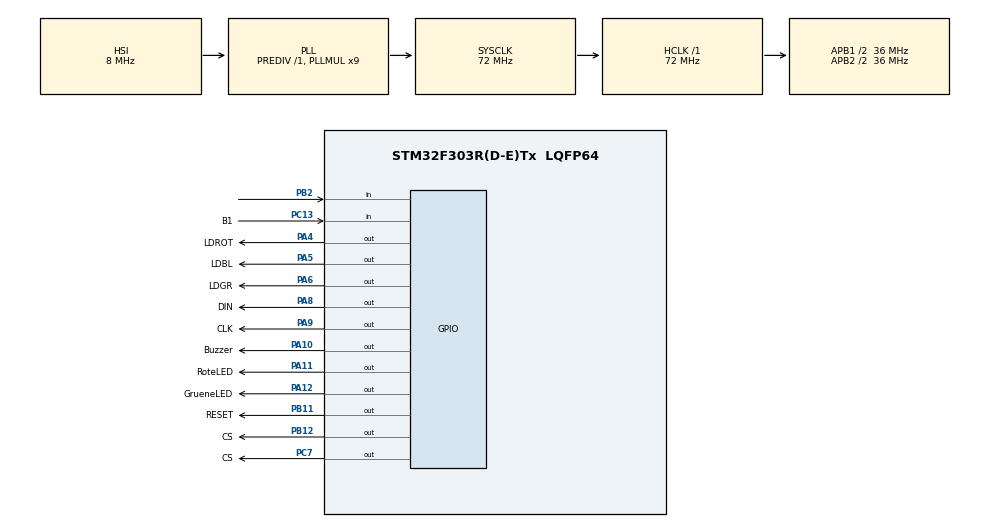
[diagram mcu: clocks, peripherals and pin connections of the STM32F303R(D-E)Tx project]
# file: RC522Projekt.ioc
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ADC1.Channel-2\#ChannelRegularConversion=ADC_CHANNEL_2
ADC1.NbrOfConversionFlag=1
ADC1.Offset-2\#ChannelRegularConversion=0
ADC1.OffsetNumber-2\#ChannelRegularConversion=ADC_OFFSET_NONE
ADC1.Rank-2\#ChannelRegularConversion=1
ADC1.SamplingTime-2\#ChannelRegularConversion=ADC_SAMPLETIME_1CYCLE_5
ADC1.master=1
I2C1.Timing=0x00201D2B
Mcu.Family=STM32F3
Mcu.Name=STM32F303R(D-E)Tx
Mcu.Package=LQFP64
NVIC.ForceEnableDMAInit=true
NVIC.PriorityFilter=0
NVIC.TIM6_DAC1_IRQn=true\:0\:0\:false\:false\:true\:true\:true\:true
PA0.GPIO_PuPd=GPIO_PULLDOWN
PA0.Signal=S_TIM2_CH1
PA1.Signal=ADC1_IN2
PA10.GPIO_Label=Buzzer
PA10.Signal=GPIO_Output
PA11.GPIO_Label=RoteLED
PA11.Signal=GPIO_Output
PA12.GPIO_Label=GrueneLED
PA12.Signal=GPIO_Output
PA15.GPIO_PuPd=GPIO_PULLUP
PA15.Signal=I2C1_SCL
PA4.GPIO_Label=LDROT
PA4.Signal=GPIO_Output
PA5.GPIO_Label=LDBL
PA5.Signal=GPIO_Output
PA6.GPIO_Label=LDGR
PA6.Signal=GPIO_Output
PA8.GPIO_Label=DIN
PA8.Signal=GPIO_Output
PA9.GPIO_Label=CLK
PA9.Signal=GPIO_Output
PB11.GPIO_Label=RESET
PB11.Signal=GPIO_Output
PB12.GPIO_Label=CS
PB12.Signal=GPIO_Output
PB13.Signal=SPI2_SCK
PB14.Signal=SPI2_MISO
PB15.Signal=SPI2_MOSI
PB2.GPIO_PuPd=GPIO_PULLUP
PB2.Signal=GPIO_Input
PB7.GPIO_PuPd=GPIO_PULLUP
PB7.Signal=I2C1_SDA
PC13.GPIO_Label=B1
PC13.Signal=GPIO_Input
PC7.GPIO_Label=CS
PC7.Signal=GPIO_Output
ProjectManager.HeapSize=0x200
ProjectManager.StackSize=0x400
ProjectManager.TargetToolchain=STM32CubeIDE
RCC.AHBFreq_Value=72000000
RCC.APB1CLKDivider=RCC_HCLK_DIV2
RCC.APB1Freq_Value=36000000
RCC.APB1TimFreq_Value=72000000
RCC.APB2CLKDivider=RCC_HCLK_DIV2
RCC.APB2Freq_Value=36000000
RCC.APB2TimFreq_Value=72000000
RCC.CortexFreq_Value=72000000
RCC.HCLKFreq_Value=72000000
RCC.HSE_VALUE=8000000
RCC.HSI_VALUE=8000000
RCC.PLLMUL=RCC_PLL_MUL9
RCC.SYSCLKFreq_VALUE=72000000
RCC.SYSCLKSource=RCC_SYSCLKSOURCE_PLLCLK
RCC.USBFreq_Value=48000000
SPI2.BaudRatePrescaler=SPI_BAUDRATEPRESCALER_32
SPI2.CLKPhase=SPI_PHASE_1EDGE
SPI2.CLKPolarity=SPI_POLARITY_LOW
SPI2.CalculateBaudRate=1.125 MBits/s
SPI2.DataSize=SPI_DATASIZE_8BIT
SPI2.Direction=SPI_DIRECTION_2LINES
SPI2.Mode=SPI_MODE_MASTER
SPI2.NSS=SPI_NSS_SOFT
TIM2.Channel-PWM\ Generation1\ CH1=TIM_CHANNEL_1
TIM2.Period=1000-1
TIM2.Prescaler=1440-1
TIM6.Period=36000-1
TIM6.Prescaler=2-1
VP_TIM2_VS_ControllerModePWMFunctional.Mode=PWM Generation1 CH1
VP_TIM6_VS_ClockSourceINT.Mode=Enable_Timer
board=custom

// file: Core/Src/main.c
/* USER CODE BEGIN Header */
/**
  ******************************************************************************
  * @file           : main.c
  * @brief          : Main program body
  ******************************************************************************
  * @attention
  *
  * Copyright (c) 2026 STMicroelectronics.
  * All rights reserved.
  *
  * This software is licensed under terms that can be found in the LICENSE file
  * in the root directory of this software component.
  * If no LICENSE file comes with this software, it is provided AS-IS.
  *
  ******************************************************************************
  */
/* USER CODE END Header */
#include "main.h"

/* USER CODE BEGIN Includes */
#include <stdio.h>
#include "MFRC522_STM32.h"
#include "ssd1306.h"
#include "ssd1306_fonts.h"
#include "ssd1306_conf.h"
#include "access_control.h"
#include <stdbool.h>
#include "servo.h"
#include "joystick.h"
/* USER CODE END Includes */

ADC_HandleTypeDef hadc1;

I2C_HandleTypeDef hi2c1;

SPI_HandleTypeDef hspi2;

TIM_HandleTypeDef htim2;
TIM_HandleTypeDef htim6;

/* USER CODE BEGIN PV */
volatile float aktuelle_position = 90.0f;
volatile int8_t speed_faktor = 1;
volatile bool sweep_modus = false;
/* USER CODE END PV */

void SystemClock_Config(void);
static void MX_GPIO_Init(void);
static void MX_SPI2_Init(void);
static void MX_I2C1_Init(void);
static void MX_TIM2_Init(void);
static void MX_TIM6_Init(void);
static void MX_ADC1_Init(void);
/* USER CODE BEGIN PFP */
static void Display_Aktualisieren(void);
/* USER CODE END PFP */

/* USER CODE BEGIN 0 */
MFRC522_t rfID = {&hspi2, CS_GPIO_Port, CS_Pin, RESET_GPIO_Port, RESET_Pin};

// Aktualisierung der OLED-Anzeige (SSD1306, 128x64) ueber I2C
static void Display_Aktualisieren(void)
{
    static uint32_t letztes_update = 0;
    static int8_t vorheriges_entsperrt = -1;
    static int8_t vorheriger_alarm = -1;
    static bool vorheriger_admin_lockout = false;
    static uint8_t vorherige_fehlversuche_in_folge = 0;
    static int8_t vorheriger_speed = -1;
    static int vorheriger_winkel = -1;
    static LearnState_t vorheriger_learn_state = LEARN_INAKTIV;
    static uint32_t vorherige_restzeit = 0;
    static bool vorheriger_sweep = false;
    static bool vorheriger_falsch_gesperrt = false;

    // Rate-Limiting fuer I2C-Uebertragungen zur Vermeidung von Bus-Blockaden
    uint32_t min_intervall = sweep_modus ? 150 : 50;
    if (HAL_GetTick() - letztes_update < min_intervall) {
        return;
    }

    bool entsperrt = AccessControl_IsUnlocked();
    bool alarm = AccessControl_AlarmAktiv();
    bool admin_lockout = AccessControl_IsAdminLockout();
    uint8_t fehlversuche_in_folge = AccessControl_GetConsecutiveFailures();
    int winkel_int = (int)aktuelle_position;
    LearnState_t learn_state = AccessControl_GetLearnState();
    uint32_t restzeit = AccessControl_GetLearnTimeoutRemaining();
    bool falsch_gesperrt = AccessControl_IsWrongCardBlocked();

    // Redraw nur bei Zustandsaenderungen durchfuehren
    if (entsperrt == vorheriges_entsperrt &&
        alarm == vorheriger_alarm &&
        admin_lockout == vorheriger_admin_lockout &&
        fehlversuche_in_folge == vorherige_fehlversuche_in_folge &&
        speed_faktor == vorheriger_speed &&
        winkel_int == vorheriger_winkel &&
        learn_state == vorheriger_learn_state &&
        restzeit == vorherige_restzeit &&
        sweep_modus == vorheriger_sweep &&
        falsch_gesperrt == vorheriger_falsch_gesperrt) {
        return;
    }

    letztes_update = HAL_GetTick();
    vorheriges_entsperrt = entsperrt;
    vorheriger_alarm = alarm;
    vorheriger_admin_lockout = admin_lockout;
    vorherige_fehlversuche_in_folge = fehlversuche_in_folge;
    vorheriger_speed = speed_faktor;
    vorheriger_winkel = winkel_int;
    vorheriger_learn_state = learn_state;
    vorherige_restzeit = restzeit;
    vorheriger_sweep = sweep_modus;
    vorheriger_falsch_gesperrt = falsch_gesperrt;

    ssd1306_Fill(Black);

    char buffer[32];

    if (admin_lockout) {
        // Anzeige: Sicherheits-Lockout nach 5 Fehlversuchen
        ssd1306_SetCursor(15, 6);
        ssd1306_WriteString("GESPERRT!", Font_11x18, White);
        ssd1306_SetCursor(15, 26);
        ssd1306_WriteString("5 Fehlversuche", Font_7x10, White);
        ssd1306_SetCursor(1, 39);
        ssd1306_WriteString("Admin-Karte noetig", Font_7x10, White);
        ssd1306_SetCursor(15, 51);
        ssd1306_WriteString("zum Entsperren", Font_7x10, White);
    } else if (learn_state != LEARN_INAKTIV) {
        // Anzeige: Zweistufiger Anlernmodus
        if (learn_state == LEARN_WARTE_NEUE_KARTE) {
            ssd1306_SetCursor(5, 4);
            ssd1306_WriteString("1. NEUE KARTE", Font_7x10, White);
            ssd1306_SetCursor(5, 20);
            ssd1306_WriteString("Karte anhalten", Font_7x10, White);
            sprintf(buffer, "Timeout: %lu s", restzeit);
            ssd1306_SetCursor(5, 36);
            ssd1306_WriteString(buffer, Font_7x10, White);
            ssd1306_SetCursor(5, 52);
            ssd1306_WriteString("B1: Abbruch", Font_7x10, White);
        } else if (learn_state == LEARN_WARTE_ADMIN_KARTE) {
            ssd1306_SetCursor(5, 4);
            ssd1306_WriteString("2. BESTAETIGEN", Font_7x10, White);
            ssd1306_SetCursor(5, 20);
            ssd1306_WriteString("Admin vorhalten", Font_7x10, White);
            sprintf(buffer, "Timeout: %lu s", restzeit);
            ssd1306_SetCursor(5, 36);
            ssd1306_WriteString(buffer, Font_7x10, White);
            ssd1306_SetCursor(5, 52);
            ssd1306_WriteString("B1: Abbruch", Font_7x10, White);
        } else if (learn_state == LEARN_ERFOLGREICH) {
            ssd1306_SetCursor(25, 12);
            ssd1306_WriteString("ERFOLG!", Font_11x18, White);
            ssd1306_SetCursor(5, 36);
            ssd1306_WriteString("Karte gespeichert", Font_7x10, White);
        } else if (learn_state == LEARN_BEREITS_BEKANNT) {
            ssd1306_SetCursor(25, 12);
            ssd1306_WriteString("HINWEIS", Font_11x18, White);
            ssd1306_SetCursor(8, 36);
            ssd1306_WriteString("Bereits bekannt!", Font_7x10, White);
        } else {
            ssd1306_SetCursor(25, 12);
            ssd1306_WriteString("ABBRUCH", Font_11x18, White);
            ssd1306_SetCursor(8, 36);
            ssd1306_WriteString("Nicht bestaetigt", Font_7x10, White);
        }
    } else if (alarm) {
        // Anzeige: Alarmzustand mit Fehlversuchs-Zaehler
        ssd1306_SetCursor(30, 6);
        ssd1306_WriteString("ALARM!", Font_11x18, White);
        if (fehlversuche_in_folge > 0) {
            snprintf(buffer, sizeof(buffer), "Fehlversuch %u/5", fehlversuche_in_folge);
            ssd1306_SetCursor(11, 27);
            ssd1306_WriteString(buffer, Font_7x10, White);
        } else {
            ssd1306_SetCursor(18, 27);
            ssd1306_WriteString("Kein Zutritt!", Font_7x10, White);
        }
        ssd1306_SetCursor(18, 40);
        ssd1306_WriteString("Kein Zutritt!", Font_7x10, White);
        ssd1306_SetCursor(15, 52);
        ssd1306_WriteString("B1: Quittieren", Font_7x10, White);
    } else if (entsperrt) {
        if (falsch_gesperrt) {
            // Warnanzeige: Verriegelung durch abweichende UID abgewiesen
            ssd1306_SetCursor(20, 4);
            ssd1306_WriteString("ACHTUNG!", Font_11x18, White);
            ssd1306_SetCursor(15, 25);
            ssd1306_WriteString("Falsche Karte!", Font_7x10, White);
            ssd1306_SetCursor(8, 38);
            ssd1306_WriteString("Nur Freischalter", Font_7x10, White);
            ssd1306_SetCursor(18, 50);
            ssd1306_WriteString("kann sperren!", Font_7x10, White);
        } else {
            // Anzeige: System freigegeben
            snprintf(buffer, sizeof(buffer), "Hallo %s!", AccessControl_GetActiveCardName());
            ssd1306_SetCursor(5, 4);
            ssd1306_WriteString(buffer, Font_7x10, White);

            if (sweep_modus) {
                sprintf(buffer, "SWEEP >>> Spd:%d", speed_faktor);
            } else {
                sprintf(buffer, "W:%3d*   Spd:%d", winkel_int, speed_faktor);
            }
            ssd1306_SetCursor(5, 18);
            ssd1306_WriteString(buffer, Font_7x10, White);

            // Grafische Balkenanzeige fuer den Servowinkel
            ssd1306_DrawRectangle(5, 34, 122, 46, White);
            uint8_t bar_width = (uint8_t)(((uint32_t)winkel_int * 114) / 180);
            if (bar_width > 0) {
                if (bar_width > 114) bar_width = 114;
                ssd1306_FillRectangle(7, 36, 7 + bar_width, 44, White);
            }

            ssd1306_SetCursor(5, 50);
            ssd1306_WriteString("0*           180*", Font_7x10, White);
        }
    } else {
        // Anzeige: System verriegelt
        ssd1306_SetCursor(20, 6);
        ssd1306_WriteString("GESPERRT", Font_11x18, White);
        ssd1306_SetCursor(15, 28);
        ssd1306_WriteString("Karte oder PIN", Font_7x10, White);
        sprintf(buffer, "OK:%lu  Fehl:%lu", AccessControl_GetSuccessfulScans(), AccessControl_GetFailedScans());
        ssd1306_SetCursor(5, 40);
        ssd1306_WriteString(buffer, Font_7x10, White);
        ssd1306_SetCursor(18, 52);
        ssd1306_WriteString("B1: Anlernen", Font_7x10, White);
    }

    ssd1306_UpdateScreen();
}
/* USER CODE END 0 */

int main(void)
{

  /* MCU Configuration--------------------------------------------------------*/

  /* Reset of all peripherals, Initializes the Flash interface and the Systick. */
  HAL_Init();

  /* Configure the system clock */
  SystemClock_Config();

  /* Initialize all configured peripherals */
  MX_GPIO_Init();
  MX_SPI2_Init();
  MX_I2C1_Init();
  MX_TIM2_Init();
  MX_TIM6_Init();
  MX_ADC1_Init();
  /* USER CODE BEGIN 2 */
  ssd1306_Init();
  ssd1306_Fill(Black);
  ssd1306_SetCursor(10, 20);
  ssd1306_WriteString("Starte...", Font_11x18, White);
  ssd1306_UpdateScreen();

  // Peripheriemodule und Treiber initialisieren
  MFRC522_Init(&rfID);
  AccessControl_Init(&rfID);
  Servo_Init(&htim2, TIM_CHANNEL_1);
  Servo_SetAngle(90);
  Joystick_Init(&hadc1, ADC_CHANNEL_2, ADC_CHANNEL_3, SW_GPIO_Port, SW_Pin);

  // Basis-Timer TIM6 fuer zyklische Regler- und Steuerungs-Tasks starten
  HAL_TIM_Base_Start_IT(&htim6);

  /* USER CODE END 2 */

  /* Infinite loop */
  /* USER CODE BEGIN WHILE */
  uint32_t letzte_aktivitaet = HAL_GetTick();
  bool b1_war_gedrueckt = false;
  bool system_war_entsperrt = false;

  while (1)
  {
      // 1. RFID-Task abarbeiten (Polling, Transponder-Erkennung, Timeout-Management)
      AccessControl_Task();

      // Flankenerkennung der Freigabe: Aktivitaetszeitstempel synchronisieren
      bool system_ist_entsperrt = AccessControl_IsUnlocked();
      if (system_ist_entsperrt && !system_war_entsperrt) {
          letzte_aktivitaet = HAL_GetTick();
      }
      system_war_entsperrt = system_ist_entsperrt;

      // 2. Taster B1 (PC13) abfragen (Entprellung per Flankenerkennung)
      bool b1_ist_gedrueckt = (HAL_GPIO_ReadPin(B1_GPIO_Port, B1_Pin) == GPIO_PIN_RESET);
      if (b1_ist_gedrueckt && !b1_war_gedrueckt) {
          if (AccessControl_IsAdminLockout()) {
              // Im Sicherheits-Lockout sind Tasteraktionen gesperrt
          } else if (AccessControl_AlarmAktiv()) {
              AccessControl_ResetAlarm(); // Alarm quittieren
          } else if (AccessControl_GetState() == STATUS_ANLERNEN) {
              AccessControl_CancelLearn(); // Anlernmodus manuell abbrechen
          } else {
              AccessControl_StartLearn();  // Zweistufigen Anlernprozess initialisieren
          }
      }
      b1_war_gedrueckt = b1_ist_gedrueckt;

      // 3. Joystick-Abtastung im 10-ms-Raster
      static uint32_t lastJoyCheck = 0;
      if (HAL_GetTick() - lastJoyCheck >= 10) {
          lastJoyCheck = HAL_GetTick();
          Joystick_Update();

          // Im verriegelten Zustand: Auswertung der PIN-Gestenabfolge (gesperrt bei Admin-Lockout)
          if (!AccessControl_IsUnlocked() && !AccessControl_IsAdminLockout()) {
              if (Joystick_CheckSecretPin()) {
                  AccessControl_UnlockViaPin();
                  letzte_aktivitaet = HAL_GetTick();
              }
          }
      }

      // 4. Betriebsmodi bei aktivem Systemzugriff
      if (AccessControl_IsUnlocked()) {
          // Kurzer Tasterklick: Geschwindigkeitsstufe zyklisch inkrementieren (1..4)
          if (Joystick_GetButtonClicked()) {
              if (++speed_faktor > 4) {
                  speed_faktor = 1;
              }
              letzte_aktivitaet = HAL_GetTick();
          }

          // Langer Tastendruck (> 800 ms): Automatischen Sweep-Modus umschalten
          if (Joystick_GetButtonHeld()) {
              sweep_modus = !sweep_modus;
              letzte_aktivitaet = HAL_GetTick();
          }

          // Manuelle Achsenabweichung: Aktivitaets-Timer zuruecksetzen, bei starker Auslenkung Sweep beenden
          int32_t x_abw = Joystick_GetX();
          if (x_abw < -100 || x_abw > 100) {
              letzte_aktivitaet = HAL_GetTick();
              if (sweep_modus && (x_abw < -400 || x_abw > 400)) {
                  sweep_modus = false;
              }
          }

          // Bei aktivem Sweep: Auto-Lock durch fortlaufende Bewegung zurueckstellen
          if (sweep_modus) {
              letzte_aktivitaet = HAL_GetTick();
          }

          // Auto-Lock: Nach 15 Sekunden ohne Interaktion automatisch verriegeln
          if (!sweep_modus && (HAL_GetTick() - letzte_aktivitaet >= 15000)) {
              AccessControl_Lock();
              sweep_modus = false;
              Servo_SetAngle(90);
              aktuelle_position = 90.0f;
              letzte_aktivitaet = HAL_GetTick();
          }
      } else {
          // Im verriegelten Zustand Sweep deaktivieren
          sweep_modus = false;
      }

      // 5. Displayausgabe aktualisieren
      Display_Aktualisieren();

    /* USER CODE END WHILE */

  }
}

void SystemClock_Config(void)
{
  RCC_OscInitTypeDef RCC_OscInitStruct = {0};
  RCC_ClkInitTypeDef RCC_ClkInitStruct = {0};
  RCC_PeriphCLKInitTypeDef PeriphClkInit = {0};

  /** Initializes the RCC Oscillators according to the specified parameters
  * in the RCC_OscInitTypeDef structure.
  */
  RCC_OscInitStruct.OscillatorType = RCC_OSCILLATORTYPE_HSI;
  RCC_OscInitStruct.HSIState = RCC_HSI_ON;
  RCC_OscInitStruct.HSICalibrationValue = RCC_HSICALIBRATION_DEFAULT;
  RCC_OscInitStruct.PLL.PLLState = RCC_PLL_ON;
  RCC_OscInitStruct.PLL.PLLSource = RCC_PLLSOURCE_HSI;
  RCC_OscInitStruct.PLL.PLLMUL = RCC_PLL_MUL9;
  RCC_OscInitStruct.PLL.PREDIV = RCC_PREDIV_DIV1;
  if (HAL_RCC_OscConfig(&RCC_OscInitStruct) != HAL_OK)
  {
    Error_Handler();
  }

  /** Initializes the CPU, AHB and APB buses clocks
  */
  RCC_ClkInitStruct.ClockType = RCC_CLOCKTYPE_HCLK|RCC_CLOCKTYPE_SYSCLK
                              |RCC_CLOCKTYPE_PCLK1|RCC_CLOCKTYPE_PCLK2;
  RCC_ClkInitStruct.SYSCLKSource = RCC_SYSCLKSOURCE_PLLCLK;
  RCC_ClkInitStruct.AHBCLKDivider = RCC_SYSCLK_DIV1;
  RCC_ClkInitStruct.APB1CLKDivider = RCC_HCLK_DIV2;
  RCC_ClkInitStruct.APB2CLKDivider = RCC_HCLK_DIV2;

  if (HAL_RCC_ClockConfig(&RCC_ClkInitStruct, FLASH_LATENCY_2) != HAL_OK)
  {
    Error_Handler();
  }
  PeriphClkInit.PeriphClockSelection = RCC_PERIPHCLK_I2C1|RCC_PERIPHCLK_ADC12
                              |RCC_PERIPHCLK_TIM2;
  PeriphClkInit.Adc12ClockSelection = RCC_ADC12PLLCLK_DIV1;
  PeriphClkInit.I2c1ClockSelection = RCC_I2C1CLKSOURCE_HSI;
  PeriphClkInit.Tim2ClockSelection = RCC_TIM2CLK_HCLK;
  if (HAL_RCCEx_PeriphCLKConfig(&PeriphClkInit) != HAL_OK)
  {
    Error_Handler();
  }
}

static void MX_ADC1_Init(void)
{

  ADC_MultiModeTypeDef multimode = {0};
  ADC_ChannelConfTypeDef sConfig = {0};

  /** Common config
  */
  hadc1.Instance = ADC1;
  hadc1.Init.ClockPrescaler = ADC_CLOCK_ASYNC_DIV1;
  hadc1.Init.Resolution = ADC_RESOLUTION_12B;
  hadc1.Init.ScanConvMode = ADC_SCAN_DISABLE;
  hadc1.Init.ContinuousConvMode = DISABLE;
  hadc1.Init.DiscontinuousConvMode = DISABLE;
  hadc1.Init.ExternalTrigConvEdge = ADC_EXTERNALTRIGCONVEDGE_NONE;
  hadc1.Init.ExternalTrigConv = ADC_SOFTWARE_START;
  hadc1.Init.DataAlign = ADC_DATAALIGN_RIGHT;
  hadc1.Init.NbrOfConversion = 1;
  hadc1.Init.DMAContinuousRequests = DISABLE;
  hadc1.Init.EOCSelection = ADC_EOC_SINGLE_CONV;
  hadc1.Init.LowPowerAutoWait = DISABLE;
  hadc1.Init.Overrun = ADC_OVR_DATA_OVERWRITTEN;
  if (HAL_ADC_Init(&hadc1) != HAL_OK)
  {
    Error_Handler();
  }

  /** Configure the ADC multi-mode
  */
  multimode.Mode = ADC_MODE_INDEPENDENT;
  if (HAL_ADCEx_MultiModeConfigChannel(&hadc1, &multimode) != HAL_OK)
  {
    Error_Handler();
  }

  /** Configure Regular Channel
  */
  sConfig.Channel = ADC_CHANNEL_2;
  sConfig.Rank = ADC_REGULAR_RANK_1;
  sConfig.SingleDiff = ADC_SINGLE_ENDED;
  sConfig.SamplingTime = ADC_SAMPLETIME_1CYCLE_5;
  sConfig.OffsetNumber = ADC_OFFSET_NONE;
  sConfig.Offset = 0;
  if (HAL_ADC_ConfigChannel(&hadc1, &sConfig) != HAL_OK)
  {
    Error_Handler();
  }

}

static void MX_I2C1_Init(void)
{

  hi2c1.Instance = I2C1;
  hi2c1.Init.Timing = 0x00201D2B;
  hi2c1.Init.OwnAddress1 = 0;
  hi2c1.Init.AddressingMode = I2C_ADDRESSINGMODE_7BIT;
  hi2c1.Init.DualAddressMode = I2C_DUALADDRESS_DISABLE;
  hi2c1.Init.OwnAddress2 = 0;
  hi2c1.Init.OwnAddress2Masks = I2C_OA2_NOMASK;
  hi2c1.Init.GeneralCallMode = I2C_GENERALCALL_DISABLE;
  hi2c1.Init.NoStretchMode = I2C_NOSTRETCH_DISABLE;
  if (HAL_I2C_Init(&hi2c1) != HAL_OK)
  {
    Error_Handler();
  }

  /** Configure Analogue filter
  */
  if (HAL_I2CEx_ConfigAnalogFilter(&hi2c1, I2C_ANALOGFILTER_ENABLE) != HAL_OK)
  {
    Error_Handler();
  }

  /** Configure Digital filter
  */
  if (HAL_I2CEx_ConfigDigitalFilter(&hi2c1, 0) != HAL_OK)
  {
    Error_Handler();
  }

}

static void MX_SPI2_Init(void)
{

  /* SPI2 parameter configuration*/
  hspi2.Instance = SPI2;
  hspi2.Init.Mode = SPI_MODE_MASTER;
  hspi2.Init.Direction = SPI_DIRECTION_2LINES;
  hspi2.Init.DataSize = SPI_DATASIZE_8BIT;
  hspi2.Init.CLKPolarity = SPI_POLARITY_LOW;
  hspi2.Init.CLKPhase = SPI_PHASE_1EDGE;
  hspi2.Init.NSS = SPI_NSS_SOFT;
  hspi2.Init.BaudRatePrescaler = SPI_BAUDRATEPRESCALER_32;
  hspi2.Init.FirstBit = SPI_FIRSTBIT_MSB;
  hspi2.Init.TIMode = SPI_TIMODE_DISABLE;
  hspi2.Init.CRCCalculation = SPI_CRCCALCULATION_DISABLE;
  hspi2.Init.CRCPolynomial = 7;
  hspi2.Init.CRCLength = SPI_CRC_LENGTH_DATASIZE;
  hspi2.Init.NSSPMode = SPI_NSS_PULSE_ENABLE;
  if (HAL_SPI_Init(&hspi2) != HAL_OK)
  {
    Error_Handler();
  }

}

static void MX_TIM2_Init(void)
{

  TIM_ClockConfigTypeDef sClockSourceConfig = {0};
  TIM_MasterConfigTypeDef sMasterConfig = {0};
  TIM_OC_InitTypeDef sConfigOC = {0};

  htim2.Instance = TIM2;
  htim2.Init.Prescaler = 1440-1;
  htim2.Init.CounterMode = TIM_COUNTERMODE_UP;
  htim2.Init.Period = 1000-1;
  htim2.Init.ClockDivision = TIM_CLOCKDIVISION_DIV1;
  htim2.Init.AutoReloadPreload = TIM_AUTORELOAD_PRELOAD_DISABLE;
  if (HAL_TIM_Base_Init(&htim2) != HAL_OK)
  {
    Error_Handler();
  }
  sClockSourceConfig.ClockSource = TIM_CLOCKSOURCE_INTERNAL;
  if (HAL_TIM_ConfigClockSource(&htim2, &sClockSourceConfig) != HAL_OK)
  {
    Error_Handler();
  }
  if (HAL_TIM_PWM_Init(&htim2) != HAL_OK)
  {
    Error_Handler();
  }
  sMasterConfig.MasterOutputTrigger = TIM_TRGO_RESET;
  sMasterConfig.MasterSlaveMode = TIM_MASTERSLAVEMODE_DISABLE;
  if (HAL_TIMEx_MasterConfigSynchronization(&htim2, &sMasterConfig) != HAL_OK)
  {
    Error_Handler();
  }
  sConfigOC.OCMode = TIM_OCMODE_PWM1;
  sConfigOC.Pulse = 0;
  sConfigOC.OCPolarity = TIM_OCPOLARITY_HIGH;
  sConfigOC.OCFastMode = TIM_OCFAST_DISABLE;
  if (HAL_TIM_PWM_ConfigChannel(&htim2, &sConfigOC, TIM_CHANNEL_1) != HAL_OK)
  {
    Error_Handler();
  }
  HAL_TIM_MspPostInit(&htim2);

}

static void MX_TIM6_Init(void)
{

  TIM_MasterConfigTypeDef sMasterConfig = {0};

  htim6.Instance = TIM6;
  htim6.Init.Prescaler = 2-1;
  htim6.Init.CounterMode = TIM_COUNTERMODE_UP;
  htim6.Init.Period = 36000-1;
  htim6.Init.AutoReloadPreload = TIM_AUTORELOAD_PRELOAD_DISABLE;
  if (HAL_TIM_Base_Init(&htim6) != HAL_OK)
  {
    Error_Handler();
  }
  sMasterConfig.MasterOutputTrigger = TIM_TRGO_RESET;
  sMasterConfig.MasterSlaveMode = TIM_MASTERSLAVEMODE_DISABLE;
  if (HAL_TIMEx_MasterConfigSynchronization(&htim6, &sMasterConfig) != HAL_OK)
  {
    Error_Handler();
  }

}

static void MX_GPIO_Init(void)
{
  GPIO_InitTypeDef GPIO_InitStruct = {0};

  /* GPIO Ports Clock Enable */
  __HAL_RCC_GPIOC_CLK_ENABLE();
  __HAL_RCC_GPIOF_CLK_ENABLE();
  __HAL_RCC_GPIOA_CLK_ENABLE();
  __HAL_RCC_GPIOB_CLK_ENABLE();

  /*Configure GPIO pin Output Level */
  HAL_GPIO_WritePin(GPIOA, LDROT_Pin|LDBL_Pin|LDGR_Pin, GPIO_PIN_RESET);

  /*Configure GPIO pin Output Level */
  HAL_GPIO_WritePin(GPIOB, RESET_Pin|CS_Pin, GPIO_PIN_RESET);

  /*Configure GPIO pin : B1_Pin */
  GPIO_InitStruct.Pin = B1_Pin;
  GPIO_InitStruct.Mode = GPIO_MODE_IT_FALLING;
  GPIO_InitStruct.Pull = GPIO_NOPULL;
  HAL_GPIO_Init(B1_GPIO_Port, &GPIO_InitStruct);

  /*Configure GPIO pin : SW_Pin */
  GPIO_InitStruct.Pin = SW_Pin;
  GPIO_InitStruct.Mode = GPIO_MODE_INPUT;
  GPIO_InitStruct.Pull = GPIO_PULLUP;
  HAL_GPIO_Init(SW_GPIO_Port, &GPIO_InitStruct);

  /*Configure GPIO pins : LDROT_Pin LDBL_Pin LDGR_Pin */
  GPIO_InitStruct.Pin = LDROT_Pin|LDBL_Pin|LDGR_Pin;
  GPIO_InitStruct.Mode = GPIO_MODE_OUTPUT_PP;
  GPIO_InitStruct.Pull = GPIO_NOPULL;
  GPIO_InitStruct.Speed = GPIO_SPEED_FREQ_LOW;
  HAL_GPIO_Init(GPIOA, &GPIO_InitStruct);

  /*Configure GPIO pins : RESET_Pin CS_Pin */
  GPIO_InitStruct.Pin = RESET_Pin|CS_Pin;
  GPIO_InitStruct.Mode = GPIO_MODE_OUTPUT_PP;
  GPIO_InitStruct.Pull = GPIO_NOPULL;
  GPIO_InitStruct.Speed = GPIO_SPEED_FREQ_LOW;
  HAL_GPIO_Init(GPIOB, &GPIO_InitStruct);

}

/* USER CODE BEGIN 4 */

void HAL_TIM_PeriodElapsedCallback(TIM_HandleTypeDef *htim) {
    if (htim->Instance == TIM6) {
        static uint8_t joyTick = 0;
        if (++joyTick >= 10) {
            joyTick = 0;

            // Im verriegelten Zustand: Mittelposition (90 Grad) erzwingen
            if (!AccessControl_IsUnlocked()) {
                Servo_Sweep(speed_faktor, false);
                if (aktuelle_position != 90.0f) {
                    aktuelle_position = 90.0f;
                    Servo_SetAngle(90);
                }
                return;
            }

            // Manuelle Servopositionierung ueber Joystick-Auslenkung
            if (!sweep_modus) {
                Servo_Sweep(speed_faktor, false);
                int32_t x_abw = Joystick_GetX();
                if (x_abw != 0) {
                    aktuelle_position += ((float)x_abw * 0.0003f * (float)speed_faktor);
                    if (aktuelle_position > 180.0f) aktuelle_position = 180.0f;
                    if (aktuelle_position < 0.0f)   aktuelle_position = 0.0f;

                    Servo_SetAngle((uint8_t)aktuelle_position);
                }
            } else {
                // Automatische Oszillation (Sweep) im 10-ms-Interrupt
                Servo_Sweep(speed_faktor, true);
                aktuelle_position = (float)Servo_GetAngle();
            }
        }
    }
}
/* USER CODE END 4 */

void Error_Handler(void)
{
  __disable_irq();
  while (1)
  {
  }
}
